# CY8C5888AXI_LP096 register map
File version: 0.1
CY8C58LP
Registers are 8-bit, read-write, no defined reset value unless marked. A register's access mark holds for its fields unless they carry their own. Offsets are from the block's base; lines under a group give offsets from that group; [hi:lo] are bit positions; {n}, {i} and the like mark numbered series; 'fields as' and 'values as' point back to an identical list; <NAME> marks a mode.

## Memory map
0x00000000 TIA_PD
0x00000000 ADC_SAR_PD — SAR ADC
0x00000000 UART
0x00000000 I2C

## ADC_SAR_PD — SAR ADC
Base 0x00000000
0x40004614 SAR_TR0 — SAR trim register
{0x40005900+i} SAR_CSR{i} (i=0..6) — SAR status and control register {i}
0x40005B20 SAR_SW0 — SAR Analog Routing Register 0
{0x40005B20+i} SAR_SW{i} (i=2..4) — SAR Analog Routing Register {i}
0x40005B26 SAR_SW6 — SAR Analog Routing Register 6
0x40005B27 SAR_CLK — SAR Clock Selection Register
0x40005BA0 SAR_WRK 16-bit — SAR working register

## UART
Base 0x00000000
0x4000642D RX_UART_RX_ADDRESS1 — RX Address1 Register
0x4000643D RX_UART_RX_ADDRESS2 — RX Address2 Register
0x4000644B TX_UART_TX_DATA — TX Data Register
0x4000644D RX_UART_RX_DATA — RX Data Register
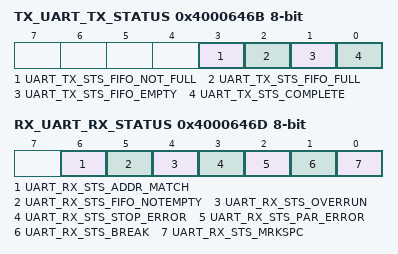
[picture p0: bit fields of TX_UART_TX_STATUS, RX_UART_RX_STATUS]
0x4000646B TX_UART_TX_STATUS — TX status register
  [3] UART_TX_STS_FIFO_NOT_FULL ro, [2] UART_TX_STS_FIFO_FULL ro, [1] UART_TX_STS_FIFO_EMPTY ro, [0] UART_TX_STS_COMPLETE ro
0x4000646D RX_UART_RX_STATUS — RX status register
  [6] UART_RX_STS_ADDR_MATCH ro, [5] UART_RX_STS_FIFO_NOTEMPTY ro, [4] UART_RX_STS_OVERRUN ro, [3] UART_RX_STS_STOP_ERROR ro, [2] UART_RX_STS_PAR_ERROR ro, [1] UART_RX_STS_BREAK ro, [0] UART_RX_STS_MRKSPC ro

## I2C
Base 0x00000000
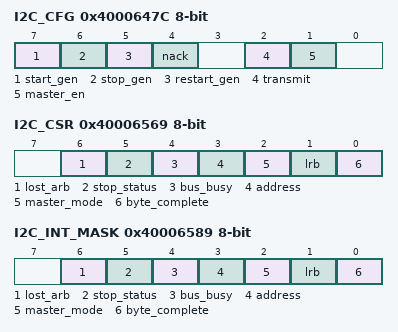
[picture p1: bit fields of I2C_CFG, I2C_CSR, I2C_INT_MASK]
0x4000647C I2C_CFG — I2C Configuration Register
  [7] start_gen — Set to 1 to generate a Start condition on the bus. This bit must be cleared by firmware before initiating the next transaction.
  [6] stop_gen — Set to 1 to generate a Stop condition on the bus. This bit must be cleared by firmware before initiating the next transaction.
  [5] restart_gen — Set to 1 to generate a Restart condition on the bus. This bit must be cleared by firmware after a Restart condition is generated.
  [4] nack — Set to 1 to NAK the next read byte. Clear to ACK next read byte. This bit must be cleared by firmware between bytes.
  [2] transmit — Set to 1 to set the current mode to transmit or clear to 0 to receive a byte of data. This bit must be cleared by firmware before starting the next transmit or receive transaction.
  [1] master_en — Set to 1 to enable the master functionality.
0x4000650A I2C_DATA
  [7:0] data — Read received data or write data to transmit.
0x40006569 I2C_CSR — I2C Status Register
  [6] lost_arb ro — If set, indicates arbitration was lost (multi-master and multi-master-slave modes).
  [5] stop_status ro — If set, indicates a Stop condition was detected on the bus.
  [4] bus_busy ro — If set, indicates the bus is busy. Data is currently being transmitted or received.
  [3] address ro — Address detection. If set, indicates that an address byte was sent.
  [2] master_mode ro — Indicates that a valid Start condition was generated and a hardware device is operating as bus master.
  [1] lrb ro — Last Received Bit. Indicates the state of the last received bit, which is the ACK/NAK received for the last byte transmitted. Cleared = ACK and set = NAK.
  [0] byte_complete ro — Transmit or receive status since the last read of this register. In Transmit mode this bit indicates that eight bits of data plus ACK/NAK have been transmitted since the last read. In Receive mode this bit indicates that eight bits of data have been received since the last read of this register.
0x40006589 I2C_INT_MASK — I2C Interrupt Enable Mask
  [6] lost_arb — Enables interrupt from the corresponding bit in status register.
  [5] stop_status — Enables interrupt from the corresponding bit in status register.
  [4] bus_busy — Enables interrupt from the corresponding bit in status register.
  [3] address — Enables interrupt from the corresponding bit in status register.
  [2] master_mode — Enables interrupt from the corresponding bit in status register.
  [1] lrb — Enables interrupt from the corresponding bit in status register.
  [0] byte_complete — Enables interrupt from the corresponding bit in status register.
